# MKM33ZA5 register map
Vendor: Freescale Semiconductor, Inc.; File version: 1.6
CPU: CM0PLUS r0p0, little endian, no MPU, no FPU, 0x2 interrupt priority bits, 0x0 interrupts
Registers are 32-bit, read-write, reset 0x0 unless marked. A register's access mark holds for its fields unless they carry their own. Offsets are from the block's base; [hi:lo] are bit positions; {n}, {i} and the like mark numbered series; 'fields as' and 'values as' point back to an identical list.

## FTFA_FlashConfig — Flash configuration field
Base 0x00000400; register names take the prefix NV_
0x00 BACKKEY3 8-bit ro reset 0xFF — Backdoor Comparison Key 3.
  [7:0] KEY — Backdoor Comparison Key.
0x01 BACKKEY2 8-bit ro reset 0xFF — Backdoor Comparison Key 2.
  [7:0] KEY — Backdoor Comparison Key.
0x02 BACKKEY1 8-bit ro reset 0xFF — Backdoor Comparison Key 1.
  [7:0] KEY — Backdoor Comparison Key.
0x03 BACKKEY0 8-bit ro reset 0xFF — Backdoor Comparison Key 0.
  [7:0] KEY — Backdoor Comparison Key.
0x04 BACKKEY7 8-bit ro reset 0xFF — Backdoor Comparison Key 7.
  [7:0] KEY — Backdoor Comparison Key.
0x05 BACKKEY6 8-bit ro reset 0xFF — Backdoor Comparison Key 6.
  [7:0] KEY — Backdoor Comparison Key.
0x06 BACKKEY5 8-bit ro reset 0xFF — Backdoor Comparison Key 5.
  [7:0] KEY — Backdoor Comparison Key.
0x07 BACKKEY4 8-bit ro reset 0xFF — Backdoor Comparison Key 4.
  [7:0] KEY — Backdoor Comparison Key.
0x08 FPROT3 8-bit ro reset 0xFF — Non-volatile P-Flash Protection 1 - Low Register
  [7:0] PROT — P-Flash Region Protect
0x09 FPROT2 8-bit ro reset 0xFF — Non-volatile P-Flash Protection 1 - High Register
  [7:0] PROT — P-Flash Region Protect
0x0A FPROT1 8-bit ro reset 0xFF — Non-volatile P-Flash Protection 0 - Low Register
  [7:0] PROT — P-Flash Region Protect
0x0B FPROT0 8-bit ro reset 0xFF — Non-volatile P-Flash Protection 0 - High Register
  [7:0] PROT — P-Flash Region Protect
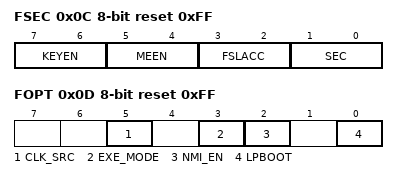
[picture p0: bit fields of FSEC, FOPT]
0x0C FSEC 8-bit ro reset 0xFF — Non-volatile Flash Security Register
  [7:6] KEYEN — Backdoor Key Security Enable
    2=Backdoor key access enabled; 3=Backdoor key access disabled
  [5:4] MEEN
    2=Mass erase is disabled; 3=Mass erase is enabled
  [3:2] FSLACC — Freescale Failure Analysis Access Code
    2=Freescale factory access denied; 3=Freescale factory access granted
  [1:0] SEC — Flash Security
    2=MCU security status is unsecure; 3=MCU security status is secure
0x0D FOPT 8-bit ro reset 0xFF — Non-volatile Flash Option Register
  [5] CLK_SRC
    0=Externally supplied clock used by Flash; 1=Internal clock source used by Flash
  [3] EXE_MODE
    0=Execution Mode is RUN Mode; 1=Execution Mode is VLPR Mode
  [2] NMI_EN
    0=NMI interrupts are always blocked; 1=NMI_b pin/interrupts reset default to enabled
  [0] LPBOOT
    0=Low-power boot; 1=Normal boot

## AIPS — AIPS-Lite Bridge
Base 0x40000000; register names take the prefix AIPS_
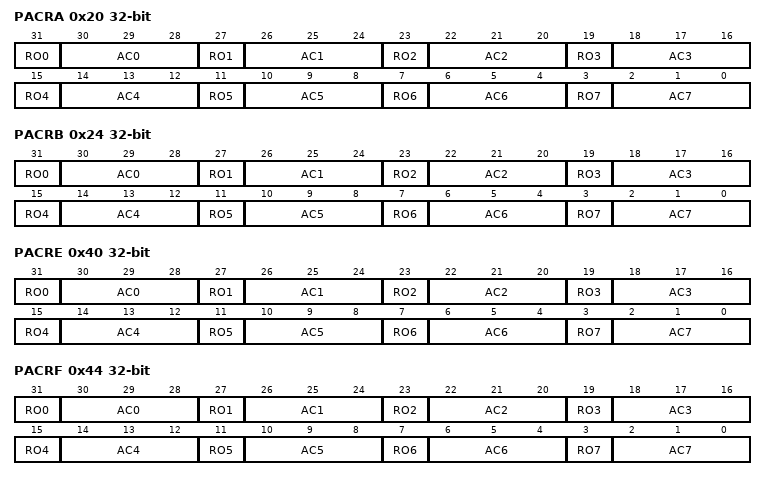
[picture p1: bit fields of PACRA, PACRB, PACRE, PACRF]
0x20 PACRA — Peripheral Access Control Register
  [31-4n] RO{n} (n=0..7) — Read Only
    0=Writes to corresponding AC field are allowed; 1=Writes to corresponding AC field are ignored
  [30-4n:28-4n] AC{n} (n=0..7) — Attribute Check
0x24 PACRB — Peripheral Access Control Register
  fields as PACRA
0x40 PACRE — Peripheral Access Control Register
  fields as PACRA
0x44 PACRF — Peripheral Access Control Register
  fields as PACRA
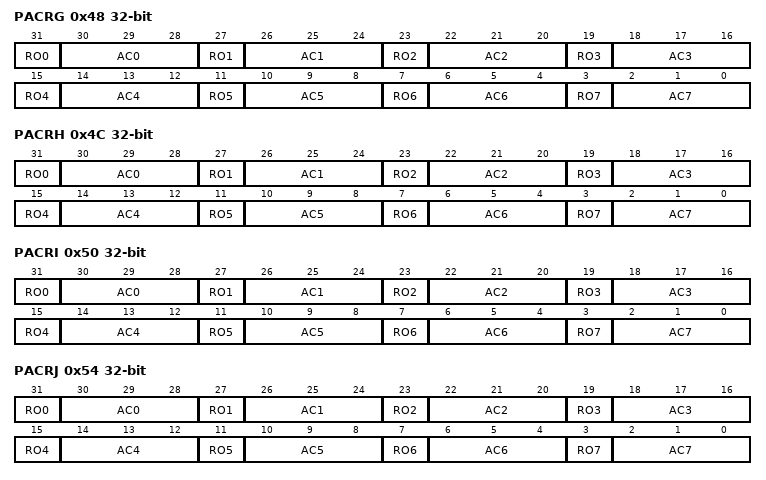
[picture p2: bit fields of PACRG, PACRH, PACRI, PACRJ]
0x48 PACRG — Peripheral Access Control Register
  fields as PACRA
0x4C PACRH — Peripheral Access Control Register
  fields as PACRA
0x50 PACRI — Peripheral Access Control Register
  fields as PACRA
0x54 PACRJ — Peripheral Access Control Register
  fields as PACRA
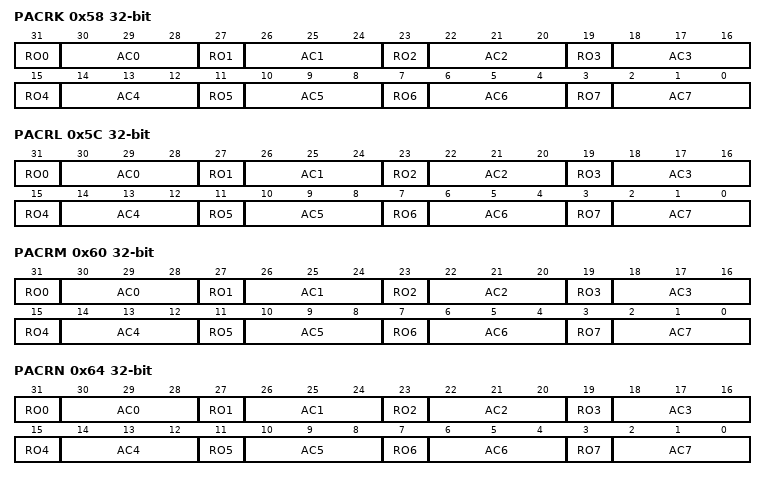
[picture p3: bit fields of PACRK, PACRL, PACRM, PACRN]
0x58 PACRK — Peripheral Access Control Register
  fields as PACRA
0x5C PACRL — Peripheral Access Control Register
  fields as PACRA
0x60 PACRM — Peripheral Access Control Register
  fields as PACRA
0x64 PACRN — Peripheral Access Control Register
  fields as PACRA
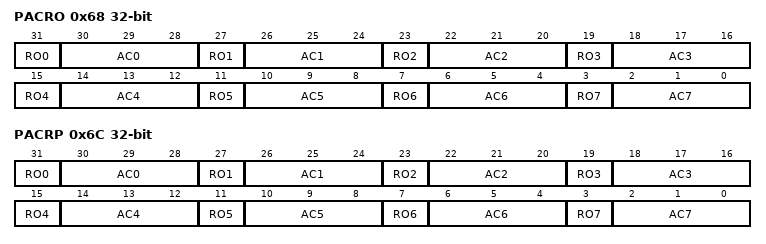
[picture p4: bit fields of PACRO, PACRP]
0x68 PACRO — Peripheral Access Control Register
  fields as PACRA
0x6C PACRP — Peripheral Access Control Register
  fields as PACRA

## DMAMUX0 — DMA channel multiplexor
Base 0x40021000; register names take the prefix DMAMUX0_
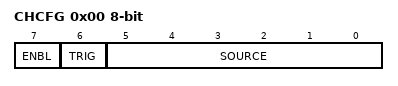
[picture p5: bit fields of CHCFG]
0x00 CHCFG 8-bit — Channel Configuration register
  [7] ENBL — DMA Channel Enable
    0=DMA channel is disabled. This mode is primarily used during configuration of the DMAMux. The DMA has separate channel enables/disables, which should be used to disable or reconfigure a DMA channel.; 1=DMA channel is enabled
  [6] TRIG — DMA Channel Trigger Enable
    0=Triggering is disabled. If triggering is disabled and ENBL is set, the DMA Channel will simply route the specified source to the DMA channel. (Normal mode); 1=Triggering is enabled. If triggering is enabled and ENBL is set, the DMAMUX is in Periodic Trigger mode.
  [5:0] SOURCE — DMA Channel Source (Slot)

## DMAMUX1 — DMA channel multiplexor
Base 0x40022000; register names take the prefix DMAMUX1_
Registers as DMAMUX0.

## DMAMUX2 — DMA channel multiplexor
Base 0x40023000; register names take the prefix DMAMUX2_
Registers as DMAMUX0.

## DMAMUX3 — DMA channel multiplexor
Base 0x40024000; register names take the prefix DMAMUX3_
Registers as DMAMUX0.
